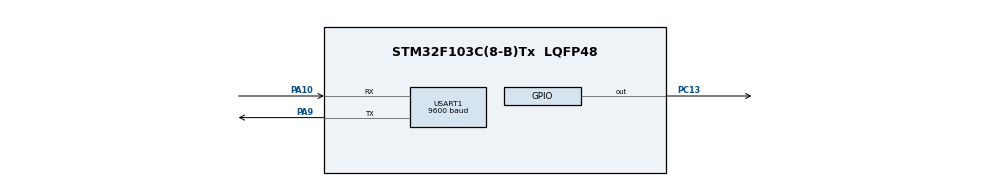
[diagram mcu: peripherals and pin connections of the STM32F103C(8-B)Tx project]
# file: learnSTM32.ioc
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IWDG.Prescaler=IWDG_PRESCALER_4
IWDG.Reload=4095
Mcu.Family=STM32F1
Mcu.Name=STM32F103C(8-B)Tx
Mcu.Package=LQFP48
NVIC.PriorityGroup=NVIC_PRIORITYGROUP_4
NVIC.TIM1_UP_IRQn=true\:0\:0\:false\:false\:true\:false\:true
NVIC.TimeBase=TIM1_UP_IRQn
NVIC.TimeBaseIP=TIM1
NVIC.USART1_IRQn=true\:0\:0\:false\:false\:true\:true\:true
PA10.Mode=Asynchronous
PA10.Signal=USART1_RX
PA13.Mode=JTAG_4_pins
PA13.Signal=SYS_JTMS-SWDIO
PA14.Mode=JTAG_4_pins
PA14.Signal=SYS_JTCK-SWCLK
PA15.Mode=JTAG_4_pins
PA15.Signal=SYS_JTDI
PA9.Mode=Asynchronous
PA9.Signal=USART1_TX
PB3.Mode=JTAG_4_pins
PB3.Signal=SYS_JTDO-TRACESWO
PC13-TAMPER-RTC.GPIO_Speed=GPIO_SPEED_FREQ_LOW
PC13-TAMPER-RTC.PinState=GPIO_PIN_SET
PC13-TAMPER-RTC.Signal=GPIO_Output
PD0-OSC_IN.Mode=HSE-External-Oscillator
PD0-OSC_IN.Signal=RCC_OSC_IN
PD1-OSC_OUT.Mode=HSE-External-Oscillator
PD1-OSC_OUT.Signal=RCC_OSC_OUT
ProjectManager.HeapSize=0x200
ProjectManager.StackSize=0x400
ProjectManager.TargetToolchain=STM32CubeIDE
RCC.APB1Freq_Value=8000000
RCC.APB2Freq_Value=8000000
RCC.USBFreq_Value=8000000
USART1.BaudRate=9600
USART1.VirtualMode=VM_ASYNC
VP_IWDG_VS_IWDG.Mode=IWDG_Activate
VP_SYS_VS_tim1.Mode=TIM1
board=custom

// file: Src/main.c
/* USER CODE BEGIN Header */
/**
  ******************************************************************************
  * @file           : main.c
  * @brief          : Main program body
  ******************************************************************************
  * @attention
  *
  * <h2><center>&copy; Copyright (c) 2019 STMicroelectronics.
  * All rights reserved.</center></h2>
  *
  * This software component is licensed by ST under BSD 3-Clause license,
  * the "License"; You may not use this file except in compliance with the
  * License. You may obtain a copy of the License at:
  *                        opensource.org/licenses/BSD-3-Clause
  *
  ******************************************************************************
  */
/* USER CODE END Header */

#include "main.h"

IWDG_HandleTypeDef hiwdg;

UART_HandleTypeDef huart1;

void SystemClock_Config(void);
static void MX_GPIO_Init(void);
static void MX_USART1_UART_Init(void);
static void MX_IWDG_Init(void);

/* USER CODE BEGIN 0 */
uint8_t aRxBuffer[1];
uint8_t handleStatus=0;
void c13LedFlash()
{
	HAL_GPIO_WritePin(GPIOC, GPIO_PIN_13, GPIO_PIN_RESET);
	HAL_Delay(200);
	HAL_GPIO_WritePin(GPIOC, GPIO_PIN_13, GPIO_PIN_SET);
	HAL_Delay(200);

}

void HAL_UART_RxCpltCallback(UART_HandleTypeDef *huart)
{
	handleStatus=1;
	HAL_UART_Transmit(&huart1 ,(uint8_t*)aRxBuffer,sizeof(aRxBuffer),0xFFFF);

	//HAL_UART_Transmit(&huart1 ,(uint8_t*)"\r\n",sizeof("\r\n"),0xFFFF);

	HAL_UART_Receive_IT(&huart1,(uint8_t*)aRxBuffer,sizeof(aRxBuffer));

	handleStatus=0;
}

void SendATcommand(){

	uint8_t name[] = "AT+NAME=\"zeta_bluetooth\"\r\n";
	uint8_t hosten[] = "AT+ROLE=0\r\n";
	uint8_t starten[] = "AT+STARTEN=0\r\n";

	  HAL_UART_Transmit(&huart1 ,(uint8_t*)name,sizeof(name),0xFFFF);
	  HAL_UART_Transmit(&huart1 ,(uint8_t*)hosten,sizeof(hosten),0xFFFF);
	  HAL_UART_Transmit(&huart1 ,(uint8_t*)starten,sizeof(starten),0xFFFF);

}

/* USER CODE END 0 */

int main(void)
{

  /* MCU Configuration--------------------------------------------------------*/

  /* Reset of all peripherals, Initializes the Flash interface and the Systick. */
  HAL_Init();

  /* Configure the system clock */
  SystemClock_Config();

  /* Initialize all configured peripherals */
  MX_GPIO_Init();
  MX_USART1_UART_Init();
  MX_IWDG_Init();
  /* USER CODE BEGIN 2 */
  SendATcommand();
  //first Receive function....
  HAL_UART_Receive_IT(&huart1,(uint8_t*)aRxBuffer,sizeof(aRxBuffer));
  /* USER CODE END 2 */

  /* Infinite loop */
  while (1)
  {

    /* USER CODE BEGIN 3 */
	  HAL_GPIO_WritePin(GPIOC, GPIO_PIN_13, GPIO_PIN_RESET);
	  HAL_Delay(1000);
	  HAL_GPIO_WritePin(GPIOC, GPIO_PIN_13, GPIO_PIN_SET);
	  HAL_Delay(1000);
	  HAL_IWDG_Refresh(&hiwdg);
  }
  /* USER CODE END 3 */
}

void SystemClock_Config(void)
{
  RCC_OscInitTypeDef RCC_OscInitStruct = {0};
  RCC_ClkInitTypeDef RCC_ClkInitStruct = {0};

  /** Initializes the CPU, AHB and APB busses clocks
  */
  RCC_OscInitStruct.OscillatorType = RCC_OSCILLATORTYPE_HSI|RCC_OSCILLATORTYPE_LSI;
  RCC_OscInitStruct.HSIState = RCC_HSI_ON;
  RCC_OscInitStruct.HSICalibrationValue = RCC_HSICALIBRATION_DEFAULT;
  RCC_OscInitStruct.LSIState = RCC_LSI_ON;
  RCC_OscInitStruct.PLL.PLLState = RCC_PLL_NONE;
  if (HAL_RCC_OscConfig(&RCC_OscInitStruct) != HAL_OK)
  {
    Error_Handler();
  }
  /** Initializes the CPU, AHB and APB busses clocks
  */
  RCC_ClkInitStruct.ClockType = RCC_CLOCKTYPE_HCLK|RCC_CLOCKTYPE_SYSCLK
                              |RCC_CLOCKTYPE_PCLK1|RCC_CLOCKTYPE_PCLK2;
  RCC_ClkInitStruct.SYSCLKSource = RCC_SYSCLKSOURCE_HSI;
  RCC_ClkInitStruct.AHBCLKDivider = RCC_SYSCLK_DIV1;
  RCC_ClkInitStruct.APB1CLKDivider = RCC_HCLK_DIV1;
  RCC_ClkInitStruct.APB2CLKDivider = RCC_HCLK_DIV1;

  if (HAL_RCC_ClockConfig(&RCC_ClkInitStruct, FLASH_LATENCY_0) != HAL_OK)
  {
    Error_Handler();
  }
}

static void MX_IWDG_Init(void)
{

  hiwdg.Instance = IWDG;
  hiwdg.Init.Prescaler = IWDG_PRESCALER_4;
  hiwdg.Init.Reload = 4095;
  if (HAL_IWDG_Init(&hiwdg) != HAL_OK)
  {
    Error_Handler();
  }

}

static void MX_USART1_UART_Init(void)
{

  huart1.Instance = USART1;
  huart1.Init.BaudRate = 9600;
  huart1.Init.WordLength = UART_WORDLENGTH_8B;
  huart1.Init.StopBits = UART_STOPBITS_1;
  huart1.Init.Parity = UART_PARITY_NONE;
  huart1.Init.Mode = UART_MODE_TX_RX;
  huart1.Init.HwFlowCtl = UART_HWCONTROL_NONE;
  huart1.Init.OverSampling = UART_OVERSAMPLING_16;
  if (HAL_UART_Init(&huart1) != HAL_OK)
  {
    Error_Handler();
  }

}

static void MX_GPIO_Init(void)
{
  GPIO_InitTypeDef GPIO_InitStruct = {0};

  /* GPIO Ports Clock Enable */
  __HAL_RCC_GPIOC_CLK_ENABLE();
  __HAL_RCC_GPIOD_CLK_ENABLE();
  __HAL_RCC_GPIOA_CLK_ENABLE();
  __HAL_RCC_GPIOB_CLK_ENABLE();

  /*Configure GPIO pin Output Level */
  HAL_GPIO_WritePin(GPIOC, GPIO_PIN_13, GPIO_PIN_SET);

  /*Configure GPIO pin : PC13 */
  GPIO_InitStruct.Pin = GPIO_PIN_13;
  GPIO_InitStruct.Mode = GPIO_MODE_OUTPUT_PP;
  GPIO_InitStruct.Pull = GPIO_NOPULL;
  GPIO_InitStruct.Speed = GPIO_SPEED_FREQ_LOW;
  HAL_GPIO_Init(GPIOC, &GPIO_InitStruct);

}

void HAL_TIM_PeriodElapsedCallback(TIM_HandleTypeDef *htim)
{
  if (htim->Instance == TIM1) {
    HAL_IncTick();
  }
}

void Error_Handler(void)
{
}

/************************ (C) COPYRIGHT STMicroelectronics *****END OF FILE****/
